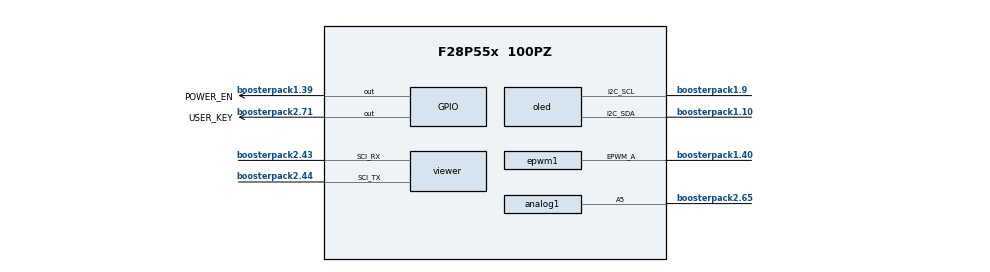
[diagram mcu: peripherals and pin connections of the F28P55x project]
/**
 *
 * @cliArgs --board "/boards/LAUNCHXL_F28P55X" --device "F28P55x" --part "F28P55x_100PZ" --package "100PZ" --context "system" --product "C2000WARE@26.02.00.00"
 * @versions {"tool":"1.28.1+4785"}
 */

/**
 * Import the modules used in this configuration.
 */
const adc     = scripting.addModule("/driverlib/adc.js", {}, false);
const adc1    = adc.addInstance();
const asysctl = scripting.addModule("/driverlib/asysctl.js");
const epwm    = scripting.addModule("/driverlib/epwm.js", {}, false);
const epwm1   = epwm.addInstance();
const gpio    = scripting.addModule("/driverlib/gpio.js", {}, false);
const gpio1   = gpio.addInstance();

/**
 * Write custom configuration values to the imported modules.
 */
adc1.$name               = "POWER_ADC";
adc1.adcClockPrescaler   = "ADC_CLK_DIV_4_0";
adc1.socHighPriorityMode = "ADC_PRI_THRU_SOC3_HIPRI";
adc1.enabledSOCs         = ["ADC_SOC_NUMBER0","ADC_SOC_NUMBER1","ADC_SOC_NUMBER2","ADC_SOC_NUMBER3"];
adc1.soc0Channel         = "ADC_CH_ADCIN6";
adc1.soc0SampleWindow    = 150;
adc1.soc0Trigger         = "ADC_TRIGGER_EPWM1_SOCA";
adc1.soc1Channel         = "ADC_CH_ADCIN7";
adc1.soc1SampleWindow    = 150;
adc1.soc1Trigger         = "ADC_TRIGGER_EPWM1_SOCA";
adc1.soc2Channel         = "ADC_CH_ADCIN5";
adc1.soc2SampleWindow    = 150;
adc1.soc2Trigger         = "ADC_TRIGGER_EPWM1_SOCA";
adc1.soc3Channel         = "ADC_CH_ADCIN9";
adc1.soc3SampleWindow    = 150;
adc1.soc3Trigger         = "ADC_TRIGGER_EPWM1_SOCA";
adc1.interruptPulseMode  = "ADC_PULSE_END_OF_CONV";
adc1.enabledInts         = ["ADC_INT_NUMBER1"];
adc1.enableInterrupt1    = true;
adc1.interrupt1SOCSource = "ADC_INT_TRIGGER_EOC3";

const analog  = scripting.addModule("/driverlib/analog.js", {}, false);
const analog1 = analog.addInstance({}, false);
analog1.$name = "myANALOGPinMux0";
adc1.analog   = analog1;
analog1.useCase = "CUSTOM";
analog1.useInterfacePins = ["A5", "A6, D14, E14, GPIO228", "A7, B30, C3, D12, E30", "A9, GPIO227"];

asysctl.analogReference        = "INTERNAL";
asysctl.analogReferenceVoltage = "1P65";

epwm1.$name                                                      = "POWER_PWM";
epwm1.epwmTimebase_hsClockDiv                                    = "EPWM_HSCLOCK_DIVIDER_1";
epwm1.epwmTimebase_counterMode                                   = "EPWM_COUNTER_MODE_UP_DOWN";
epwm1.epwmTimebase_period                                        = 3750;
epwm1.epwmTimebase_syncInPulseSource                             = "EPWM_SYNC_IN_PULSE_SRC_DISABLE";
epwm1.epwmCounterCompare_cmpA                                    = 1875;
epwm1.epwmCounterCompare_shadowLoadModeCMPA                      = "EPWM_COMP_LOAD_ON_CNTR_PERIOD";
epwm1.epwmActionQualifier_EPWM_AQ_OUTPUT_A_ON_TIMEBASE_ZERO      = "EPWM_AQ_OUTPUT_HIGH";
epwm1.epwmActionQualifier_EPWM_AQ_OUTPUT_A_ON_TIMEBASE_UP_CMPA   = "EPWM_AQ_OUTPUT_LOW";
epwm1.epwmActionQualifier_EPWM_AQ_OUTPUT_A_ON_TIMEBASE_DOWN_CMPA = "EPWM_AQ_OUTPUT_HIGH";
epwm1.epwmEventTrigger_EPWM_SOC_A_triggerEnable                  = true;
epwm1.epwmEventTrigger_EPWM_SOC_A_triggerSource                  = "EPWM_SOC_TBCTR_ZERO_OR_PERIOD";
epwm1.epwmEventTrigger_EPWM_SOC_A_triggerEventPrescalar          = "1";
epwm1.epwmEventTrigger_enableInterrupt                           = true;
epwm1.epwmEventTrigger_interruptSource                           = "EPWM_INT_TBCTR_ZERO_OR_PERIOD";
epwm1.epwmEventTrigger_interruptEventCount                       = "1";
epwm1.useCase = "CUSTOM";
epwm1.useInterfacePins = ["EPWM#_A"];
epwm1.epwm.$assign                                               = "EPWM1";
epwm1.epwm.epwm_aPin.$assign                                     = "boosterpack1.40";

gpio1.$name             = "POWER_EN";
gpio1.direction         = "GPIO_DIR_MODE_OUT";
gpio1.writeInitialValue = true;
gpio1.gpioPin.$assign   = "boosterpack1.39";

/**
 * Pinmux solution for unlocked pins/peripherals. This ensures that minor changes to the automatic solver in a future
 * version of the tool will not impact the pinmux you originally saw.  These lines can be completely deleted in order to
 * re-solve from scratch.
 */

analog1.analog.a5Pin.$assign = "boosterpack2.65";
analog1.analog["a6, d14, e14, gpio228Pin"].$assign = "boosterpack1.23";
analog1.analog["a7, b30, c3, d12, e30Pin"].$assign = "boosterpack1.6";
analog1.analog["a9, gpio227Pin"].$assign = "boosterpack2.46";

const i2c = scripting.addModule("/driverlib/i2c.js", {}, false);
const oled = i2c.addInstance();
oled.$name = "OLED_I2C";
oled.bitRate = 100000;
oled.bitCount = "I2C_BITCOUNT_8";
oled.targetAddress = 0x3c;
oled.useInterrupts = false;
oled.useFifo = true;
oled.i2c.$assign = "I2CB";
oled.i2c.i2c_sdaPin.$assign = "boosterpack1.10";
oled.i2c.i2c_sclPin.$assign = "boosterpack1.9";
const sci = scripting.addModule("/driverlib/sci.js", {}, false);
const viewer = sci.addInstance();
viewer.$name = "VIEWER_SCI";
viewer.baudRates = 115200;
viewer.useFifo = true;
viewer.useInterrupts = false;
viewer.sci.$assign = "SCIB";
viewer.sci.sci_rxPin.$assign = "boosterpack2.43";
viewer.sci.sci_txPin.$assign = "boosterpack2.44";
const key = gpio.addInstance();
key.$name = "USER_KEY";
key.padConfig = "PULLUP";
key.gpioPin.$assign = "boosterpack2.71";
